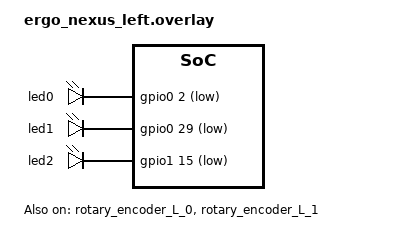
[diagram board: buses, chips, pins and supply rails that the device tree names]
#include "ergo_nexus.dtsi"


&kscan0 {
    row-gpios
        = <&gpio1 0 (GPIO_ACTIVE_HIGH | GPIO_PULL_DOWN)>
        , <&gpio0 11 (GPIO_ACTIVE_HIGH | GPIO_PULL_DOWN)>
        , <&gpio1 4 (GPIO_ACTIVE_HIGH | GPIO_PULL_DOWN)>
        , <&gpio1 6 (GPIO_ACTIVE_HIGH | GPIO_PULL_DOWN)>
        ;
	col-gpios
	    = <&gpio0 17 (GPIO_ACTIVE_HIGH)>
		, <&gpio0 20 (GPIO_ACTIVE_HIGH)>
		, <&gpio0 22 (GPIO_ACTIVE_HIGH)>
		, <&gpio0 24 (GPIO_ACTIVE_HIGH)>
		, <&gpio1 1 (GPIO_ACTIVE_HIGH)>
		, <&gpio1 2 (GPIO_ACTIVE_HIGH)>
		;
};
&rotary_encoder_L_0 {
        a-gpios = <&gpio0 10 (GPIO_ACTIVE_HIGH | GPIO_PULL_UP)>;
        b-gpios = <&gpio0 9 (GPIO_ACTIVE_HIGH | GPIO_PULL_UP)>;
		status = "okay";
};
&rotary_encoder_L_1 {
        a-gpios = <&gpio1 13 (GPIO_ACTIVE_HIGH | GPIO_PULL_UP)>;
        b-gpios = <&gpio1 11 (GPIO_ACTIVE_HIGH | GPIO_PULL_UP)>;
		status = "okay";
};
&leds {
    led0: led_0 {
        gpios = <&gpio0 2 GPIO_ACTIVE_LOW>; // red LED, connected
    };
    led1: led_1 {
        gpios = <&gpio0 29 GPIO_ACTIVE_LOW>; // green LED, connected
    };
    led2: led_2 {
        gpios = <&gpio1 15 GPIO_ACTIVE_LOW>;  // blue LED, connected
    };
};
